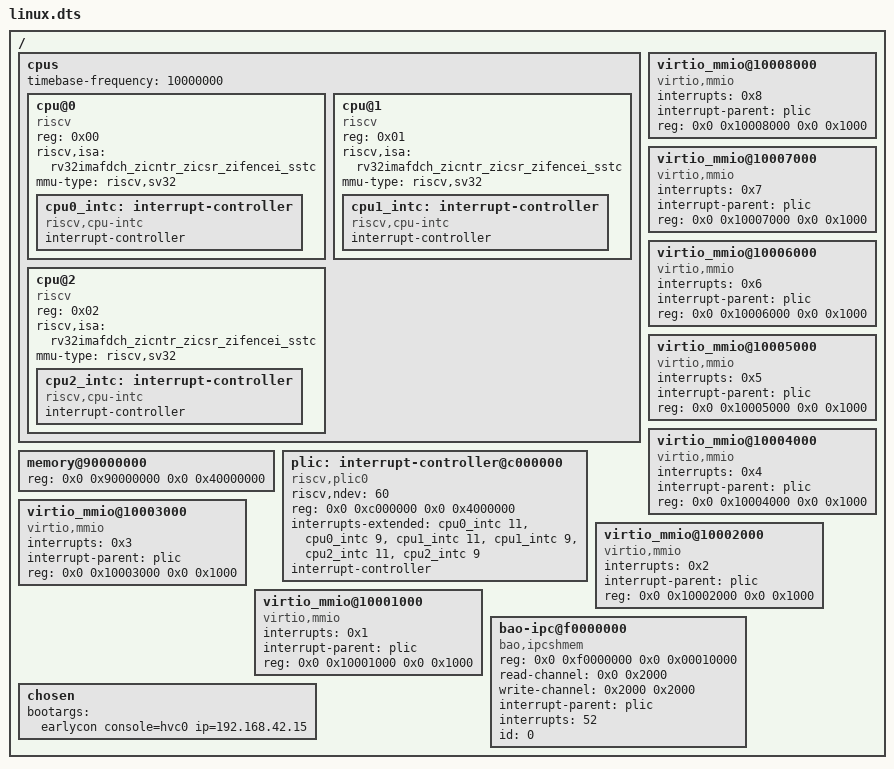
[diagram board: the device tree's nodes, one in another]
/dts-v1/;

/ {
	#address-cells = <0x02>;
	#size-cells = <0x02>;


	cpus {
		#address-cells = <0x1>;
		#size-cells = <0x0>;
		timebase-frequency = <10000000>;

		cpu@0 {
			device_type = "cpu";
			reg = <0x00>;
			status = "okay";
			compatible = "riscv";
			riscv,isa = "rv32imafdch_zicntr_zicsr_zifencei_sstc";
			mmu-type = "riscv,sv32";

			cpu0_intc: interrupt-controller {
				#interrupt-cells = <0x01>;
				interrupt-controller;
				compatible = "riscv,cpu-intc";
				phandle = <0x08>;
			};
		};

		cpu@1 {
			device_type = "cpu";
			reg = <0x01>;
			status = "okay";
			compatible = "riscv";
			riscv,isa = "rv32imafdch_zicntr_zicsr_zifencei_sstc";
			mmu-type = "riscv,sv32";

			cpu1_intc: interrupt-controller {
				#interrupt-cells = <0x01>;
				interrupt-controller;
				compatible = "riscv,cpu-intc";
				phandle = <0x06>;
			};
		};

		cpu@2 {
			device_type = "cpu";
			reg = <0x02>;
			status = "okay";
			compatible = "riscv";
			riscv,isa = "rv32imafdch_zicntr_zicsr_zifencei_sstc";
			mmu-type = "riscv,sv32";

			cpu2_intc: interrupt-controller {
				#interrupt-cells = <0x01>;
				interrupt-controller;
				compatible = "riscv,cpu-intc";
				phandle = <0x04>;
			};
		};

	};

	memory@90000000 {
		device_type = "memory";
		reg = <0x0 0x90000000 0x0 0x40000000>;
	};

	plic: interrupt-controller@c000000 {
		riscv,ndev = <60>;
		reg = <0x0 0xc000000 0x0 0x4000000>;
		interrupts-extended = <
			&cpu0_intc 11 &cpu0_intc 9 
			&cpu1_intc 11 &cpu1_intc 9 
			&cpu2_intc 11 &cpu2_intc 9
		>;
		interrupt-controller;
		compatible = "riscv,plic0";
		#interrupt-cells = <0x1>;
	};

	virtio_mmio@10008000 {
		interrupts = <0x8>;
		interrupt-parent = <&plic>;
		reg = <0x0 0x10008000 0x0 0x1000>;
		compatible = "virtio,mmio";
	};

	virtio_mmio@10007000 {
		interrupts = <0x7>;
		interrupt-parent = <&plic>;
		reg = <0x0 0x10007000 0x0 0x1000>;
		compatible = "virtio,mmio";
	};

	virtio_mmio@10006000 {
		interrupts = <0x6>;
		interrupt-parent = <&plic>;
		reg = <0x0 0x10006000 0x0 0x1000>;
		compatible = "virtio,mmio";
	};

	virtio_mmio@10005000 {
		interrupts = <0x5>;
		interrupt-parent = <&plic>;
		reg = <0x0 0x10005000 0x0 0x1000>;
		compatible = "virtio,mmio";
	};

	virtio_mmio@10004000 {
		interrupts = <0x4>;
		interrupt-parent = <&plic>;
		reg = <0x0 0x10004000 0x0 0x1000>;
		compatible = "virtio,mmio";
	};

	virtio_mmio@10003000 {
		interrupts = <0x3>;
		interrupt-parent = <&plic>;
		reg = <0x0 0x10003000 0x0 0x1000>;
		compatible = "virtio,mmio";
	};

	virtio_mmio@10002000 {
		interrupts = <0x2>;
		interrupt-parent = <&plic>;
		reg = <0x0 0x10002000 0x0 0x1000>;
		compatible = "virtio,mmio";
	};

	virtio_mmio@10001000 {
		interrupts = <0x1>;
		interrupt-parent = <&plic>;
		reg = <0x0 0x10001000 0x0 0x1000>;
		compatible = "virtio,mmio";
	};

    bao-ipc@f0000000 {
        compatible = "bao,ipcshmem";
        reg = <0x0 0xf0000000 0x0 0x00010000>;
		read-channel = <0x0 0x2000>;
		write-channel = <0x2000 0x2000>;
		interrupt-parent = <&plic>;
        interrupts = <52>;
		id = <0>;
    };

	chosen {
		bootargs = "earlycon console=hvc0 ip=192.168.42.15";
	};

};
